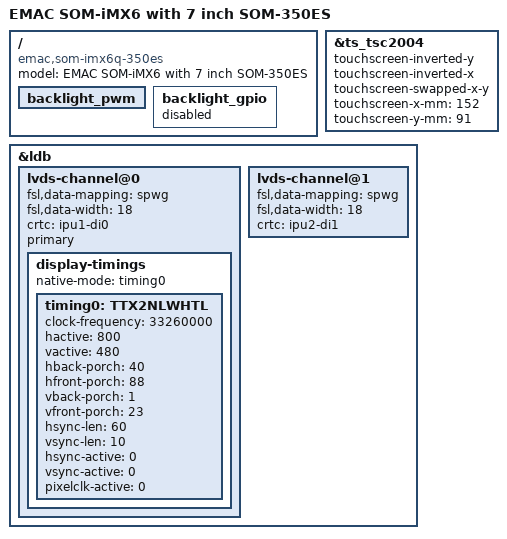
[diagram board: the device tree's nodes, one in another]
/*
 * Copyright 2022 EMAC Inc.
 *
 * Author: Joseph Mills <jmills@emacinc.com>
 *
 * This program is free software; you can redistribute it and/or modify
 * it under the terms of the GNU General Public License version 2 as
 * published by the Free Software Foundation.
 *
 */

/dts-v1/;

#include <dt-bindings/interrupt-controller/irq.h>
#include "imx6q.dtsi"
#include "som-imx6q-350es.dts"

/ {
    model = "EMAC SOM-iMX6 with 7 inch SOM-350ES";
    compatible = "emac,som-imx6q-350es", "fsl,imx6q";
    // 7 inch
    backlight_pwm: backlight_pwm {
        status = "okay";
    };
    // 10 inch
    backlight_gpio: backlight_gpio {
        status = "disabled";
    };
};

&ts_tsc2004 {
    touchscreen-inverted-y;
    touchscreen-inverted-x;
    touchscreen-swapped-x-y;
    touchscreen-x-mm = <152>;
    touchscreen-y-mm = <91>;
};

&ldb {
    status = "okay";
    lvds-channel@0 {
        fsl,data-mapping = "spwg";
        fsl,data-width = <18>;
        crtc = "ipu1-di0";
        primary;
        status = "okay";
        display-timings {
            native-mode = <&timing0>;
            timing0: TTX2NLWHTL {
                clock-frequency = <33260000>; 
                hactive = <800>;
                vactive = <480>;
                hback-porch = <40>;
                hfront-porch = <88>;
                vback-porch = <1>;
                vfront-porch = <23>;
                hsync-len = <60>;
                vsync-len = <10>;
                hsync-active = <0>;
                vsync-active = <0>;
                pixelclk-active = <0>;
            };
        };
    };

    lvds-channel@1 {
        fsl,data-mapping = "spwg";
        fsl,data-width = <18>;
        crtc = "ipu2-di1";
    };
};

